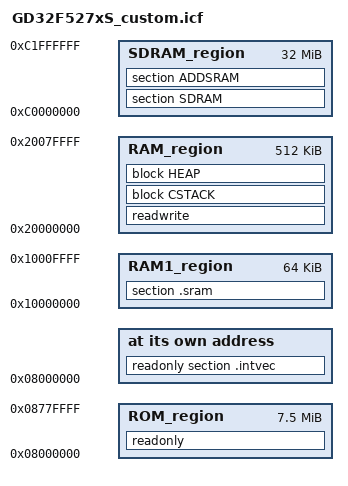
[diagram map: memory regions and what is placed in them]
/* Project linker configuration for GD32F527xS. */
define symbol __ICFEDIT_intvec_start__ = 0x08000000;
define symbol __ICFEDIT_region_ROM_start__ = 0x08000000;
define symbol __ICFEDIT_region_ROM_end__   = 0x0877FFFF;
define symbol __ICFEDIT_region_RAM_start__ = 0x20000000;
define symbol __ICFEDIT_region_RAM_end__   = 0x2007FFFF;
define symbol __region_RAM1_start__ = 0x10000000;
define symbol __region_RAM1_end__   = 0x1000FFFF;
define symbol __ICFEDIT_size_cstack__ = 0x8000;
define symbol __ICFEDIT_size_heap__   = 0x4000;

define memory mem with size = 4G;
define region ROM_region  = mem:[from __ICFEDIT_region_ROM_start__ to __ICFEDIT_region_ROM_end__];
define region RAM_region  = mem:[from __ICFEDIT_region_RAM_start__ to __ICFEDIT_region_RAM_end__];
define region RAM1_region = mem:[from __region_RAM1_start__ to __region_RAM1_end__];
define region SDRAM_region = mem:[from 0xC0000000 to 0xC1FFFFFF];

define block CSTACK with alignment = 8, size = __ICFEDIT_size_cstack__ { };
define block HEAP   with alignment = 8, size = __ICFEDIT_size_heap__ { };

initialize by copy with packing = zeros { readwrite };
do not initialize { section .noinit, section SDRAM, section ADDSRAM };

place at address mem:__ICFEDIT_intvec_start__ { readonly section .intvec };
place in ROM_region { readonly };
place in RAM1_region { section .sram };
place in SDRAM_region { section SDRAM, section ADDSRAM };
place in RAM_region { readwrite, block CSTACK, block HEAP };
